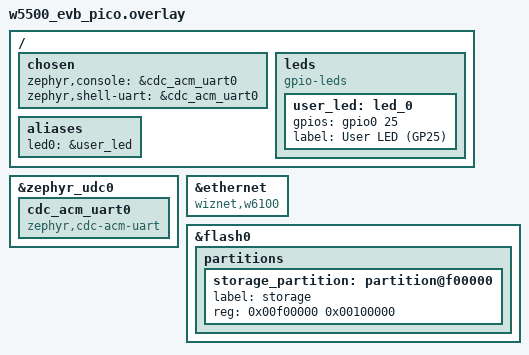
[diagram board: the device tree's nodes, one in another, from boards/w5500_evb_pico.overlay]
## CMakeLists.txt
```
# apps/pedal/CMakeLists.txt — PEDAL per-device Zephyr app (BL-015 step 4).
#
# Mintát ad: apps/estop/CMakeLists.txt — ugyanaz a felépítés. PEDAL jelenleg
# csak heartbeat csatornát publikál (`/robot/heartbeat`, 1 Hz BOOL toggle) —
# ez a régi app/ test_heartbeat-jének PEDAL-os átnevezése. A tényleges
# pedál-hardware csatornák később, dedikált backlog item alapján kerülnek be.
cmake_minimum_required(VERSION 3.20.0)

list(APPEND ZEPHYR_EXTRA_MODULES
    $ENV{ZEPHYR_BASE}/../modules/lib/micro_ros_zephyr_module/modules/libmicroros
    $ENV{W6100_MODULE_DIR})

find_package(Zephyr REQUIRED HINTS $ENV{ZEPHYR_BASE})
project(w6100_pico_bridge_pedal)

# Közös réteg
add_subdirectory(
    $ENV{COMMON_DIR}
    ${CMAKE_CURRENT_BINARY_DIR}/common)

target_sources(app PRIVATE
    src/user_channels.c
    src/pedal.c
)

target_include_directories(app PRIVATE src)
```

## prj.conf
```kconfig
# USB CDC ACM - serial konzol
CONFIG_USB_DEVICE_STACK=y
CONFIG_USB_CDC_ACM=y
CONFIG_UART_LINE_CTRL=y
CONFIG_SERIAL=y
CONFIG_CONSOLE=y
CONFIG_UART_CONSOLE=y

# Networking
CONFIG_NETWORKING=y
CONFIG_NET_L2_ETHERNET=y
CONFIG_NET_L2_ETHERNET_MGMT=y
# W6100 out-of-tree driver — modules/w6100_driver/ (backport Zephyr main
# upstream PR-ból v4.2.2 alá). Az overlay átírja a &ethernet node compatible
# mezőjét "wiznet,w6100"-ra, így a stock w5500 driver kikapcsolható.
CONFIG_ETH_W5500=n
CONFIG_ETH_W6100=y
CONFIG_NET_IPV4=y
CONFIG_NET_UDP=y
CONFIG_NET_LOG=y

# IP konfig — a tényleges beállítás config.json-ból jön (main.c)
CONFIG_NET_DHCPV4=y

# Hostname — set dynamically at runtime from node_name
CONFIG_NET_HOSTNAME_ENABLE=y
CONFIG_NET_HOSTNAME_DYNAMIC=y
CONFIG_NET_HOSTNAME="ROS_Bridge"
CONFIG_NET_HOSTNAME_MAX_LEN=63

# POSIX sockets (micro-ROS UDP transport)
CONFIG_POSIX_API=y
CONFIG_NET_SOCKETS=y

# Network buffers (RP2040: 264KB RAM)
CONFIG_NET_PKT_RX_COUNT=8
CONFIG_NET_PKT_TX_COUNT=8
CONFIG_NET_BUF_RX_COUNT=24
CONFIG_NET_BUF_TX_COUNT=24

# micro-ROS
# Az agent IP-t runtime config.json dönti el (devices/PEDAL/config.json →
# 10.0.10.1 prod). Compile-time default = prod subnet gateway, így ha a
# LittleFS config elveszik, a factory fallback is prod hálózatra néz.
CONFIG_MICROROS=y
CONFIG_MICROROS_TRANSPORT_UDP=y
CONFIG_MICROROS_AGENT_IP="10.0.10.1"
CONFIG_MICROROS_AGENT_PORT="8888"

# C++ és newlib (micro-ROS szükséges)
CONFIG_CPP=y
CONFIG_NEWLIB_LIBC=y
CONFIG_NEWLIB_LIBC_NANO=n

# Logging
CONFIG_LOG=y
CONFIG_LOG_DEFAULT_LEVEL=3
CONFIG_LOG_PROCESS_THREAD_STACK_SIZE=2048

# Random number generator (networking igényli)
CONFIG_ENTROPY_GENERATOR=y
CONFIG_TEST_RANDOM_GENERATOR=y

# Heap / Stack (micro-ROS nagyobb igény)
CONFIG_HEAP_MEM_POOL_SIZE=98304
CONFIG_MAIN_STACK_SIZE=16384

# Flash + LittleFS (config tárolás)
CONFIG_FLASH=y
CONFIG_FLASH_MAP=y
CONFIG_FLASH_PAGE_LAYOUT=y
CONFIG_FILE_SYSTEM=y
CONFIG_FILE_SYSTEM_LITTLEFS=y
CONFIG_FS_LITTLEFS_FC_HEAP_SIZE=4096

# Shell (config parancsok soros konzolon)
CONFIG_SHELL=y
CONFIG_SHELL_BACKEND_SERIAL=y
CONFIG_SHELL_STACK_SIZE=4096
CONFIG_SHELL_ARGC_MAX=8
CONFIG_SHELL_CMD_BUFF_SIZE=256
CONFIG_SHELL_BACKEND_SERIAL_RX_RING_BUFFER_SIZE=512
CONFIG_SHELL_BACKEND_SERIAL_TX_RING_BUFFER_SIZE=8192
CONFIG_SHELL_STACK_SIZE=8192
CONFIG_REBOOT=y

# Hardware watchdog (RP2040 beépített WDT)
CONFIG_WATCHDOG=y

# Hardware info (RP2040 unique device ID — used for MAC generation)
CONFIG_HWINFO=y

# --- micro-ROS entity limits ---
# Publishers: 16 csatorna + 1 diagnostics + spare = 20 (a param event publisher
#   elvetve BL-017 / ERR-032 miatt, de a slot marad spare-ként).
# Subscribers: 16 csatorna (legrosszabb eset).
# Servers: 2 user service (E-Stop, relay); a 6 param server slot törölve
#   (param_server_init() nincs a main.c-ben — config.json a forrás).
CONFIG_MICROROS_PUBLISHERS="20"
CONFIG_MICROROS_SUBSCRIBERS="16"
CONFIG_MICROROS_SERVERS="2"
CONFIG_MICROROS_CLIENTS="0"
CONFIG_MICROROS_NODES="1"

# --- GPIO interrupt (atomic flag ISR-hez) ---
# CONFIG_ATOMIC_OPERATIONS_BUILTIN nem user-configurable; RP2040-on automatikusan builtin

# --- ADC (akkumulátor feszültségmérés) ---
CONFIG_ADC=y
```

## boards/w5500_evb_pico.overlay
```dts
/*
 * apps/pedal/boards/w5500_evb_pico.overlay — PEDAL board overlay (BL-015 step 4).
 *
 * Szándékosan minimális:
 *   - user_led GP25 — link / heartbeat-active visszajelzés (közös funkció)
 *
 * Pin-allokáció szabad — a PEDAL hardware még nincs definiálva a backlog-ban.
 * NEM kerül ide: estop_btn (GP27), rc_inputs (GP2..GP7), relay_brake (GP14),
 * ADC csatorna — ezeket az E_STOP/RC device-ok tartalmazzák.
 *
 * Ethernet: a board default w5500-ot köt a &ethernet node-ra, itt
 * felülírjuk W6100-ra (out-of-tree driver: modules/w6100_driver/).
 *
 * LittleFS: a config.json perzisztens tárolása a flash utolsó 1 MB-jában
 * (offset 15 MB) — szükséges a `bridge config` shell parancsokhoz.
 */

/ {
	chosen {
		zephyr,console = &cdc_acm_uart0;
		zephyr,shell-uart = &cdc_acm_uart0;
	};

	leds {
		compatible = "gpio-leds";
		user_led: led_0 {
			gpios = <&gpio0 25 GPIO_ACTIVE_HIGH>;
			label = "User LED (GP25)";
		};
	};

	aliases {
		led0 = &user_led;
	};
};

&zephyr_udc0 {
	cdc_acm_uart0: cdc_acm_uart0 {
		compatible = "zephyr,cdc-acm-uart";
	};
};

&ethernet {
	compatible = "wiznet,w6100";
};

/* LittleFS storage partition — last 1MB of flash (offset 15MB) */
&flash0 {
	partitions {
		storage_partition: partition@f00000 {
			label = "storage";
			reg = <0x00f00000 0x00100000>;
		};
	};
};
```

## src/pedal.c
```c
#include "pedal.h"

#include <zephyr/kernel.h>
#include <zephyr/logging/log.h>

LOG_MODULE_REGISTER(pedal, LOG_LEVEL_INF);

static bool g_heartbeat = false;

static void heartbeat_read(channel_value_t *val)
{
	g_heartbeat = !g_heartbeat;
	val->b = g_heartbeat;
}

const channel_t pedal_heartbeat_channel = {
	.name      = "pedal_heartbeat",
	.topic_pub = "heartbeat",
	.topic_sub = NULL,
	.msg_type  = MSG_BOOL,
	.period_ms = 1000,
	.init      = NULL,
	.read      = heartbeat_read,
	.write     = NULL,
};
```

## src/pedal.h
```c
#ifndef PEDAL_H
#define PEDAL_H

#include "bridge/channel.h"

/* PEDAL heartbeat — publish-only BOOL toggle, 1 Hz.
 * Topic: heartbeat (ROS namespace /robot → /robot/heartbeat).
 * Verify with: ros2 topic echo /robot/heartbeat
 *
 * BL-015 step 4: a régi test_channels.c heartbeat-jének PEDAL-os átnevezése.
 * A struct .name = "pedal_heartbeat" (config.json key); a .topic_pub = "heartbeat"
 * marad a memory-rögzített BL-010+ERR-031 zöld topic kompatibilitásáért. */
extern const channel_t pedal_heartbeat_channel;

#endif /* PEDAL_H */
```

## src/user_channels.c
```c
/*
 * apps/pedal/src/user_channels.c — PEDAL per-device csatorna-regiszter (BL-015 step 4).
 *
 * Jelenleg csak a heartbeat csatorna regisztrálódik — a PEDAL device a
 * BL-015 előtt is csak smoke/health pingre volt használva (test_heartbeat).
 * A tényleges pedál-hardware csatornák később, dedikált backlog item alapján
 * kerülnek be ide.
 */

#include "user/user_channels.h"
#include "bridge/channel_manager.h"
#include "config/config.h"
#include "pedal.h"

static void register_if_enabled(const channel_t *ch)
{
	if (config_channel_enabled(ch->name)) {
		channel_register(ch);
	}
}

void user_register_channels(void)
{
	register_if_enabled(&pedal_heartbeat_channel);
}
```
